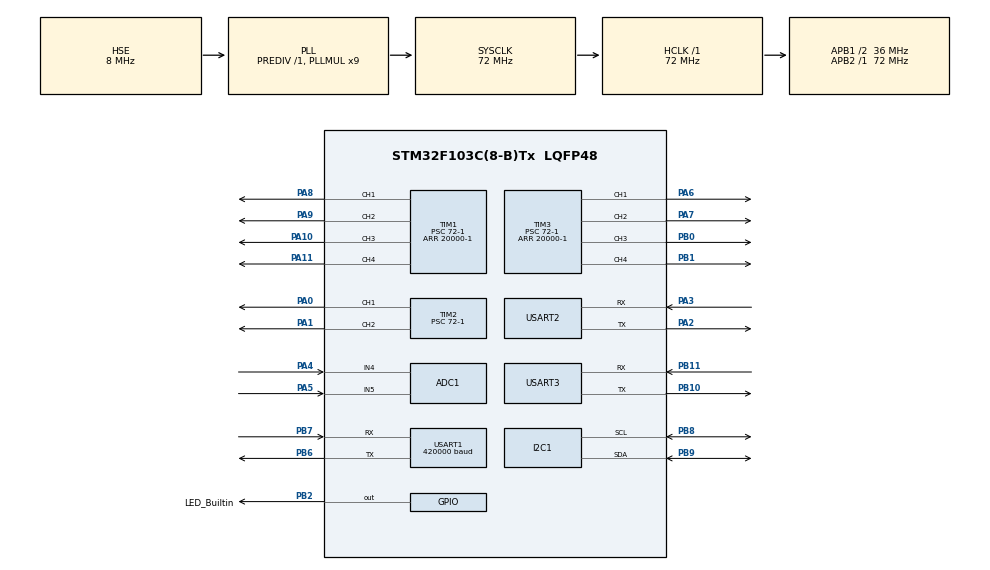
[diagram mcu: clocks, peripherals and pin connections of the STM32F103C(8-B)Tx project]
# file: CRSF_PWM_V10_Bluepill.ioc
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ADC1.Channel-0\#ChannelRegularConversion=ADC_CHANNEL_4
ADC1.NbrOfConversionFlag=1
ADC1.Rank-0\#ChannelRegularConversion=1
ADC1.SamplingTime-0\#ChannelRegularConversion=ADC_SAMPLETIME_1CYCLE_5
ADC1.master=1
Dma.ADC1.0.Direction=DMA_PERIPH_TO_MEMORY
Dma.ADC1.0.Instance=DMA1_Channel1
Dma.ADC1.0.MemDataAlignment=DMA_MDATAALIGN_HALFWORD
Dma.ADC1.0.MemInc=DMA_MINC_ENABLE
Dma.ADC1.0.Mode=DMA_NORMAL
Dma.ADC1.0.PeriphDataAlignment=DMA_PDATAALIGN_HALFWORD
Dma.ADC1.0.PeriphInc=DMA_PINC_DISABLE
Dma.ADC1.0.Priority=DMA_PRIORITY_LOW
Dma.Request0=ADC1
Mcu.Family=STM32F1
Mcu.Name=STM32F103C(8-B)Tx
Mcu.Package=LQFP48
NVIC.DMA1_Channel1_IRQn=true\:0\:0\:false\:false\:true\:false\:true\:true
NVIC.I2C1_ER_IRQn=true\:0\:0\:false\:false\:true\:true\:true\:true
NVIC.I2C1_EV_IRQn=true\:0\:0\:false\:false\:true\:true\:true\:true
NVIC.PriorityGroup=NVIC_PRIORITYGROUP_4
NVIC.USART1_IRQn=true\:0\:0\:false\:false\:true\:true\:true\:true
NVIC.USART2_IRQn=true\:3\:0\:true\:false\:true\:true\:true\:true
NVIC.USART3_IRQn=true\:1\:0\:true\:false\:true\:true\:true\:true
PA0-WKUP.Signal=S_TIM2_CH1_ETR
PA1.Signal=S_TIM2_CH2
PA10.Signal=S_TIM1_CH3
PA11.Signal=S_TIM1_CH4
PA13.Mode=Serial_Wire
PA13.Signal=SYS_JTMS-SWDIO
PA14.Mode=Serial_Wire
PA14.Signal=SYS_JTCK-SWCLK
PA2.Mode=Asynchronous
PA2.Signal=USART2_TX
PA3.GPIO_PuPd=GPIO_PULLUP
PA3.Mode=Asynchronous
PA3.Signal=USART2_RX
PA4.Signal=ADCx_IN4
PA5.Signal=ADCx_IN5
PA6.Signal=S_TIM3_CH1
PA7.Signal=S_TIM3_CH2
PA8.Signal=S_TIM1_CH1
PA9.Signal=S_TIM1_CH2
PB0.Signal=S_TIM3_CH3
PB1.Signal=S_TIM3_CH4
PB10.Mode=Asynchronous
PB10.Signal=USART3_TX
PB11.GPIO_PuPd=GPIO_PULLUP
PB11.Mode=Asynchronous
PB11.Signal=USART3_RX
PB2.GPIO_Label=LED_Builtin
PB2.Signal=GPIO_Output
PB6.Mode=Asynchronous
PB6.Signal=USART1_TX
PB7.GPIO_PuPd=GPIO_PULLUP
PB7.Mode=Asynchronous
PB7.Signal=USART1_RX
PB8.Mode=I2C
PB8.Signal=I2C1_SCL
PB9.Mode=I2C
PB9.Signal=I2C1_SDA
PC14-OSC32_IN.Mode=LSE-External-Oscillator
PC14-OSC32_IN.Signal=RCC_OSC32_IN
PC15-OSC32_OUT.Mode=LSE-External-Oscillator
PC15-OSC32_OUT.Signal=RCC_OSC32_OUT
PD0-OSC_IN.Mode=HSE-External-Oscillator
PD0-OSC_IN.Signal=RCC_OSC_IN
PD1-OSC_OUT.Mode=HSE-External-Oscillator
PD1-OSC_OUT.Signal=RCC_OSC_OUT
ProjectManager.HeapSize=0x200
ProjectManager.StackSize=0x400
ProjectManager.TargetToolchain=CMake
RCC.ADCPresc=RCC_ADCPCLK2_DIV6
RCC.AHBFreq_Value=72000000
RCC.APB1CLKDivider=RCC_HCLK_DIV2
RCC.APB1Freq_Value=36000000
RCC.APB1TimFreq_Value=72000000
RCC.APB2Freq_Value=72000000
RCC.APB2TimFreq_Value=72000000
RCC.HCLKFreq_Value=72000000
RCC.PLLMUL=RCC_PLL_MUL9
RCC.PLLSourceVirtual=RCC_PLLSOURCE_HSE
RCC.SYSCLKFreq_VALUE=72000000
RCC.SYSCLKSource=RCC_SYSCLKSOURCE_PLLCLK
RCC.USBFreq_Value=72000000
SH.ADCx_IN4.0=ADC1_IN4,IN4
SH.ADCx_IN5.0=ADC1_IN5,IN5
SH.S_TIM1_CH1.0=TIM1_CH1,PWM Generation1 CH1
SH.S_TIM1_CH2.0=TIM1_CH2,PWM Generation2 CH2
SH.S_TIM1_CH3.0=TIM1_CH3,PWM Generation3 CH3
SH.S_TIM1_CH4.0=TIM1_CH4,PWM Generation4 CH4
SH.S_TIM2_CH1_ETR.0=TIM2_CH1,PWM Generation1 CH1
SH.S_TIM2_CH2.0=TIM2_CH2,PWM Generation2 CH2
SH.S_TIM3_CH1.0=TIM3_CH1,PWM Generation1 CH1
SH.S_TIM3_CH2.0=TIM3_CH2,PWM Generation2 CH2
SH.S_TIM3_CH3.0=TIM3_CH3,PWM Generation3 CH3
SH.S_TIM3_CH4.0=TIM3_CH4,PWM Generation4 CH4
TIM1.AutoReloadPreload=TIM_AUTORELOAD_PRELOAD_ENABLE
TIM1.Channel-PWM\ Generation1\ CH1=TIM_CHANNEL_1
TIM1.Channel-PWM\ Generation2\ CH2=TIM_CHANNEL_2
TIM1.Channel-PWM\ Generation3\ CH3=TIM_CHANNEL_3
TIM1.Channel-PWM\ Generation4\ CH4=TIM_CHANNEL_4
TIM1.Period=20000-1
TIM1.Prescaler=72-1
TIM2.AutoReloadPreload=TIM_AUTORELOAD_PRELOAD_ENABLE
TIM2.Channel-PWM\ Generation1\ CH1=TIM_CHANNEL_1
TIM2.Channel-PWM\ Generation2\ CH2=TIM_CHANNEL_2
TIM2.Channel-PWM\ Generation3\ CH3=TIM_CHANNEL_3
TIM2.Channel-PWM\ Generation4\ CH4=TIM_CHANNEL_4
TIM2.Period=20000-1
TIM2.Prescaler=72-1
TIM3.AutoReloadPreload=TIM_AUTORELOAD_PRELOAD_ENABLE
TIM3.Channel-PWM\ Generation1\ CH1=TIM_CHANNEL_1
TIM3.Channel-PWM\ Generation2\ CH2=TIM_CHANNEL_2
TIM3.Channel-PWM\ Generation3\ CH3=TIM_CHANNEL_3
TIM3.Channel-PWM\ Generation4\ CH4=TIM_CHANNEL_4
TIM3.Period=20000-1
TIM3.Prescaler=72-1
USART1.BaudRate=420000
USART1.VirtualMode=VM_ASYNC
USART2.VirtualMode=VM_ASYNC
USART3.VirtualMode=VM_ASYNC
VP_TIM1_VS_ClockSourceINT.Mode=Internal
VP_TIM2_VS_ClockSourceINT.Mode=Internal
VP_TIM3_VS_ClockSourceINT.Mode=Internal
board=custom

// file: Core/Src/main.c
/* USER CODE BEGIN Header */
/**
  ******************************************************************************
  * @file           : main.c
  * @brief          : Main program body
  ******************************************************************************
  * @attention
  *
  * Copyright (c) 2026 STMicroelectronics.
  * All rights reserved.
  *
  * This software is licensed under terms that can be found in the LICENSE file
  * in the root directory of this software component.
  * If no LICENSE file comes with this software, it is provided AS-IS.
  *
  ******************************************************************************
  */
/* USER CODE END Header */
#include "main.h"

/* USER CODE BEGIN Includes */
#include <stdio.h>
#include "user_main.h"

/* USER CODE END Includes */

ADC_HandleTypeDef hadc1;
DMA_HandleTypeDef hdma_adc1;

I2C_HandleTypeDef hi2c1;

TIM_HandleTypeDef htim1;
TIM_HandleTypeDef htim2;
TIM_HandleTypeDef htim3;

UART_HandleTypeDef huart1;
UART_HandleTypeDef huart2;
UART_HandleTypeDef huart3;

void SystemClock_Config(void);
static void MX_GPIO_Init(void);
static void MX_DMA_Init(void);
static void MX_I2C1_Init(void);
static void MX_TIM1_Init(void);
static void MX_TIM2_Init(void);
static void MX_TIM3_Init(void);
static void MX_USART2_UART_Init(void);
static void MX_USART1_UART_Init(void);
static void MX_USART3_UART_Init(void);
static void MX_ADC1_Init(void);

int main(void)
{

  /* MCU Configuration--------------------------------------------------------*/

  /* Reset of all peripherals, Initializes the Flash interface and the Systick. */

  HAL_Init();

  /* Configure the system clock */
  SystemClock_Config();

  /* Initialize all configured peripherals */
  MX_GPIO_Init();
  MX_DMA_Init();
  MX_I2C1_Init();
  MX_TIM1_Init();
  MX_TIM2_Init();
  MX_TIM3_Init();
  MX_USART2_UART_Init();
  MX_USART1_UART_Init();
  MX_USART3_UART_Init();
  MX_ADC1_Init();
  /* USER CODE BEGIN 2 */
  user_init();
  /* USER CODE END 2 */

  /* Infinite loop */
  /* USER CODE BEGIN WHILE */
  while (1)
  {
    user_loop_step();
#ifdef USER_LOOP
#endif
    /* USER CODE END WHILE */

  }
}

void SystemClock_Config(void)
{
  RCC_OscInitTypeDef RCC_OscInitStruct = {0};
  RCC_ClkInitTypeDef RCC_ClkInitStruct = {0};
  RCC_PeriphCLKInitTypeDef PeriphClkInit = {0};

  /** Initializes the RCC Oscillators according to the specified parameters
  * in the RCC_OscInitTypeDef structure.
  */
  RCC_OscInitStruct.OscillatorType = RCC_OSCILLATORTYPE_HSE;
  RCC_OscInitStruct.HSEState = RCC_HSE_ON;
  RCC_OscInitStruct.HSEPredivValue = RCC_HSE_PREDIV_DIV1;
  RCC_OscInitStruct.HSIState = RCC_HSI_ON;
  RCC_OscInitStruct.PLL.PLLState = RCC_PLL_ON;
  RCC_OscInitStruct.PLL.PLLSource = RCC_PLLSOURCE_HSE;
  RCC_OscInitStruct.PLL.PLLMUL = RCC_PLL_MUL9;
  if (HAL_RCC_OscConfig(&RCC_OscInitStruct) != HAL_OK)
  {
    Error_Handler();
  }

  /** Initializes the CPU, AHB and APB buses clocks
  */
  RCC_ClkInitStruct.ClockType = RCC_CLOCKTYPE_HCLK|RCC_CLOCKTYPE_SYSCLK
                              |RCC_CLOCKTYPE_PCLK1|RCC_CLOCKTYPE_PCLK2;
  RCC_ClkInitStruct.SYSCLKSource = RCC_SYSCLKSOURCE_PLLCLK;
  RCC_ClkInitStruct.AHBCLKDivider = RCC_SYSCLK_DIV1;
  RCC_ClkInitStruct.APB1CLKDivider = RCC_HCLK_DIV2;
  RCC_ClkInitStruct.APB2CLKDivider = RCC_HCLK_DIV1;

  if (HAL_RCC_ClockConfig(&RCC_ClkInitStruct, FLASH_LATENCY_2) != HAL_OK)
  {
    Error_Handler();
  }
  PeriphClkInit.PeriphClockSelection = RCC_PERIPHCLK_ADC;
  PeriphClkInit.AdcClockSelection = RCC_ADCPCLK2_DIV6;
  if (HAL_RCCEx_PeriphCLKConfig(&PeriphClkInit) != HAL_OK)
  {
    Error_Handler();
  }
}

static void MX_ADC1_Init(void)
{

  ADC_ChannelConfTypeDef sConfig = {0};

  /** Common config
  */
  hadc1.Instance = ADC1;
  hadc1.Init.ScanConvMode = ADC_SCAN_DISABLE;
  hadc1.Init.ContinuousConvMode = DISABLE;
  hadc1.Init.DiscontinuousConvMode = DISABLE;
  hadc1.Init.ExternalTrigConv = ADC_SOFTWARE_START;
  hadc1.Init.DataAlign = ADC_DATAALIGN_RIGHT;
  hadc1.Init.NbrOfConversion = 1;
  if (HAL_ADC_Init(&hadc1) != HAL_OK)
  {
    Error_Handler();
  }

  /** Configure Regular Channel
  */
  sConfig.Channel = ADC_CHANNEL_4;
  sConfig.Rank = ADC_REGULAR_RANK_1;
  sConfig.SamplingTime = ADC_SAMPLETIME_1CYCLE_5;
  if (HAL_ADC_ConfigChannel(&hadc1, &sConfig) != HAL_OK)
  {
    Error_Handler();
  }

}

static void MX_I2C1_Init(void)
{

  hi2c1.Instance = I2C1;
  hi2c1.Init.ClockSpeed = 100000;
  hi2c1.Init.DutyCycle = I2C_DUTYCYCLE_2;
  hi2c1.Init.OwnAddress1 = 0;
  hi2c1.Init.AddressingMode = I2C_ADDRESSINGMODE_7BIT;
  hi2c1.Init.DualAddressMode = I2C_DUALADDRESS_DISABLE;
  hi2c1.Init.OwnAddress2 = 0;
  hi2c1.Init.GeneralCallMode = I2C_GENERALCALL_DISABLE;
  hi2c1.Init.NoStretchMode = I2C_NOSTRETCH_DISABLE;
  if (HAL_I2C_Init(&hi2c1) != HAL_OK)
  {
    Error_Handler();
  }

}

static void MX_TIM1_Init(void)
{

  TIM_ClockConfigTypeDef sClockSourceConfig = {0};
  TIM_MasterConfigTypeDef sMasterConfig = {0};
  TIM_OC_InitTypeDef sConfigOC = {0};
  TIM_BreakDeadTimeConfigTypeDef sBreakDeadTimeConfig = {0};

  htim1.Instance = TIM1;
  htim1.Init.Prescaler = 72-1;
  htim1.Init.CounterMode = TIM_COUNTERMODE_UP;
  htim1.Init.Period = 20000-1;
  htim1.Init.ClockDivision = TIM_CLOCKDIVISION_DIV1;
  htim1.Init.RepetitionCounter = 0;
  htim1.Init.AutoReloadPreload = TIM_AUTORELOAD_PRELOAD_ENABLE;
  if (HAL_TIM_Base_Init(&htim1) != HAL_OK)
  {
    Error_Handler();
  }
  sClockSourceConfig.ClockSource = TIM_CLOCKSOURCE_INTERNAL;
  if (HAL_TIM_ConfigClockSource(&htim1, &sClockSourceConfig) != HAL_OK)
  {
    Error_Handler();
  }
  if (HAL_TIM_PWM_Init(&htim1) != HAL_OK)
  {
    Error_Handler();
  }
  sMasterConfig.MasterOutputTrigger = TIM_TRGO_RESET;
  sMasterConfig.MasterSlaveMode = TIM_MASTERSLAVEMODE_DISABLE;
  if (HAL_TIMEx_MasterConfigSynchronization(&htim1, &sMasterConfig) != HAL_OK)
  {
    Error_Handler();
  }
  sConfigOC.OCMode = TIM_OCMODE_PWM1;
  sConfigOC.Pulse = 0;
  sConfigOC.OCPolarity = TIM_OCPOLARITY_HIGH;
  sConfigOC.OCNPolarity = TIM_OCNPOLARITY_HIGH;
  sConfigOC.OCFastMode = TIM_OCFAST_DISABLE;
  sConfigOC.OCIdleState = TIM_OCIDLESTATE_RESET;
  sConfigOC.OCNIdleState = TIM_OCNIDLESTATE_RESET;
  if (HAL_TIM_PWM_ConfigChannel(&htim1, &sConfigOC, TIM_CHANNEL_1) != HAL_OK)
  {
    Error_Handler();
  }
  if (HAL_TIM_PWM_ConfigChannel(&htim1, &sConfigOC, TIM_CHANNEL_2) != HAL_OK)
  {
    Error_Handler();
  }
  if (HAL_TIM_PWM_ConfigChannel(&htim1, &sConfigOC, TIM_CHANNEL_3) != HAL_OK)
  {
    Error_Handler();
  }
  if (HAL_TIM_PWM_ConfigChannel(&htim1, &sConfigOC, TIM_CHANNEL_4) != HAL_OK)
  {
    Error_Handler();
  }
  sBreakDeadTimeConfig.OffStateRunMode = TIM_OSSR_DISABLE;
  sBreakDeadTimeConfig.OffStateIDLEMode = TIM_OSSI_DISABLE;
  sBreakDeadTimeConfig.LockLevel = TIM_LOCKLEVEL_OFF;
  sBreakDeadTimeConfig.DeadTime = 0;
  sBreakDeadTimeConfig.BreakState = TIM_BREAK_DISABLE;
  sBreakDeadTimeConfig.BreakPolarity = TIM_BREAKPOLARITY_HIGH;
  sBreakDeadTimeConfig.AutomaticOutput = TIM_AUTOMATICOUTPUT_DISABLE;
  if (HAL_TIMEx_ConfigBreakDeadTime(&htim1, &sBreakDeadTimeConfig) != HAL_OK)
  {
    Error_Handler();
  }
  HAL_TIM_MspPostInit(&htim1);

}

static void MX_TIM2_Init(void)
{

  TIM_ClockConfigTypeDef sClockSourceConfig = {0};
  TIM_MasterConfigTypeDef sMasterConfig = {0};
  TIM_OC_InitTypeDef sConfigOC = {0};

  htim2.Instance = TIM2;
  htim2.Init.Prescaler = 72-1;
  htim2.Init.CounterMode = TIM_COUNTERMODE_UP;
  htim2.Init.Period = 20000-1;
  htim2.Init.ClockDivision = TIM_CLOCKDIVISION_DIV1;
  htim2.Init.AutoReloadPreload = TIM_AUTORELOAD_PRELOAD_ENABLE;
  if (HAL_TIM_Base_Init(&htim2) != HAL_OK)
  {
    Error_Handler();
  }
  sClockSourceConfig.ClockSource = TIM_CLOCKSOURCE_INTERNAL;
  if (HAL_TIM_ConfigClockSource(&htim2, &sClockSourceConfig) != HAL_OK)
  {
    Error_Handler();
  }
  if (HAL_TIM_PWM_Init(&htim2) != HAL_OK)
  {
    Error_Handler();
  }
  sMasterConfig.MasterOutputTrigger = TIM_TRGO_RESET;
  sMasterConfig.MasterSlaveMode = TIM_MASTERSLAVEMODE_DISABLE;
  if (HAL_TIMEx_MasterConfigSynchronization(&htim2, &sMasterConfig) != HAL_OK)
  {
    Error_Handler();
  }
  sConfigOC.OCMode = TIM_OCMODE_PWM1;
  sConfigOC.Pulse = 0;
  sConfigOC.OCPolarity = TIM_OCPOLARITY_HIGH;
  sConfigOC.OCFastMode = TIM_OCFAST_DISABLE;
  if (HAL_TIM_PWM_ConfigChannel(&htim2, &sConfigOC, TIM_CHANNEL_1) != HAL_OK)
  {
    Error_Handler();
  }
  if (HAL_TIM_PWM_ConfigChannel(&htim2, &sConfigOC, TIM_CHANNEL_2) != HAL_OK)
  {
    Error_Handler();
  }
  HAL_TIM_MspPostInit(&htim2);

}

static void MX_TIM3_Init(void)
{

  TIM_ClockConfigTypeDef sClockSourceConfig = {0};
  TIM_MasterConfigTypeDef sMasterConfig = {0};
  TIM_OC_InitTypeDef sConfigOC = {0};

  htim3.Instance = TIM3;
  htim3.Init.Prescaler = 72-1;
  htim3.Init.CounterMode = TIM_COUNTERMODE_UP;
  htim3.Init.Period = 20000-1;
  htim3.Init.ClockDivision = TIM_CLOCKDIVISION_DIV1;
  htim3.Init.AutoReloadPreload = TIM_AUTORELOAD_PRELOAD_ENABLE;
  if (HAL_TIM_Base_Init(&htim3) != HAL_OK)
  {
    Error_Handler();
  }
  sClockSourceConfig.ClockSource = TIM_CLOCKSOURCE_INTERNAL;
  if (HAL_TIM_ConfigClockSource(&htim3, &sClockSourceConfig) != HAL_OK)
  {
    Error_Handler();
  }
  if (HAL_TIM_PWM_Init(&htim3) != HAL_OK)
  {
    Error_Handler();
  }
  sMasterConfig.MasterOutputTrigger = TIM_TRGO_RESET;
  sMasterConfig.MasterSlaveMode = TIM_MASTERSLAVEMODE_DISABLE;
  if (HAL_TIMEx_MasterConfigSynchronization(&htim3, &sMasterConfig) != HAL_OK)
  {
    Error_Handler();
  }
  sConfigOC.OCMode = TIM_OCMODE_PWM1;
  sConfigOC.Pulse = 0;
  sConfigOC.OCPolarity = TIM_OCPOLARITY_HIGH;
  sConfigOC.OCFastMode = TIM_OCFAST_DISABLE;
  if (HAL_TIM_PWM_ConfigChannel(&htim3, &sConfigOC, TIM_CHANNEL_1) != HAL_OK)
  {
    Error_Handler();
  }
  if (HAL_TIM_PWM_ConfigChannel(&htim3, &sConfigOC, TIM_CHANNEL_2) != HAL_OK)
  {
    Error_Handler();
  }
  if (HAL_TIM_PWM_ConfigChannel(&htim3, &sConfigOC, TIM_CHANNEL_3) != HAL_OK)
  {
    Error_Handler();
  }
  if (HAL_TIM_PWM_ConfigChannel(&htim3, &sConfigOC, TIM_CHANNEL_4) != HAL_OK)
  {
    Error_Handler();
  }
  HAL_TIM_MspPostInit(&htim3);

}

static void MX_USART1_UART_Init(void)
{

  huart1.Instance = USART1;
  huart1.Init.BaudRate = 420000;
  huart1.Init.WordLength = UART_WORDLENGTH_8B;
  huart1.Init.StopBits = UART_STOPBITS_1;
  huart1.Init.Parity = UART_PARITY_NONE;
  huart1.Init.Mode = UART_MODE_TX_RX;
  huart1.Init.HwFlowCtl = UART_HWCONTROL_NONE;
  huart1.Init.OverSampling = UART_OVERSAMPLING_16;
  if (HAL_UART_Init(&huart1) != HAL_OK)
  {
    Error_Handler();
  }

}

static void MX_USART2_UART_Init(void)
{

  huart2.Instance = USART2;
  huart2.Init.BaudRate = 115200;
  huart2.Init.WordLength = UART_WORDLENGTH_8B;
  huart2.Init.StopBits = UART_STOPBITS_1;
  huart2.Init.Parity = UART_PARITY_NONE;
  huart2.Init.Mode = UART_MODE_TX_RX;
  huart2.Init.HwFlowCtl = UART_HWCONTROL_NONE;
  huart2.Init.OverSampling = UART_OVERSAMPLING_16;
  if (HAL_UART_Init(&huart2) != HAL_OK)
  {
    Error_Handler();
  }

}

static void MX_USART3_UART_Init(void)
{

  huart3.Instance = USART3;
  huart3.Init.BaudRate = 115200;
  huart3.Init.WordLength = UART_WORDLENGTH_8B;
  huart3.Init.StopBits = UART_STOPBITS_1;
  huart3.Init.Parity = UART_PARITY_NONE;
  huart3.Init.Mode = UART_MODE_TX_RX;
  huart3.Init.HwFlowCtl = UART_HWCONTROL_NONE;
  huart3.Init.OverSampling = UART_OVERSAMPLING_16;
  if (HAL_UART_Init(&huart3) != HAL_OK)
  {
    Error_Handler();
  }

}

static void MX_DMA_Init(void)
{

  /* DMA controller clock enable */
  __HAL_RCC_DMA1_CLK_ENABLE();

  /* DMA interrupt init */
  /* DMA1_Channel1_IRQn interrupt configuration */
  HAL_NVIC_SetPriority(DMA1_Channel1_IRQn, 0, 0);
  HAL_NVIC_EnableIRQ(DMA1_Channel1_IRQn);

}

static void MX_GPIO_Init(void)
{
  GPIO_InitTypeDef GPIO_InitStruct = {0};

  /* GPIO Ports Clock Enable */
  __HAL_RCC_GPIOC_CLK_ENABLE();
  __HAL_RCC_GPIOD_CLK_ENABLE();
  __HAL_RCC_GPIOA_CLK_ENABLE();
  __HAL_RCC_GPIOB_CLK_ENABLE();

  /*Configure GPIO pin Output Level */
  HAL_GPIO_WritePin(LED_Builtin_GPIO_Port, LED_Builtin_Pin, GPIO_PIN_RESET);

  /*Configure GPIO pin : LED_Builtin_Pin */
  GPIO_InitStruct.Pin = LED_Builtin_Pin;
  GPIO_InitStruct.Mode = GPIO_MODE_OUTPUT_PP;
  GPIO_InitStruct.Pull = GPIO_NOPULL;
  GPIO_InitStruct.Speed = GPIO_SPEED_FREQ_LOW;
  HAL_GPIO_Init(LED_Builtin_GPIO_Port, &GPIO_InitStruct);

}

void Error_Handler(void)
{
  __disable_irq();
  while (1)
  {
  }
}
